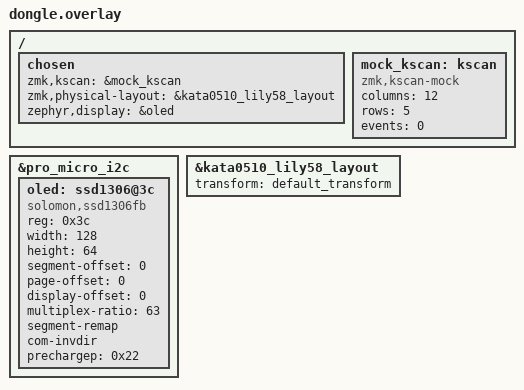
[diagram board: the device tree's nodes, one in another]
#include <dt-bindings/zmk/matrix_transform.h>
#include <layouts/kata0510/lily58.dtsi>

/ {
    chosen {
        zmk,kscan = &mock_kscan;
        zmk,physical-layout = &kata0510_lily58_layout;
        zephyr,display = &oled;
    };

    mock_kscan: kscan {
        compatible = "zmk,kscan-mock";
        columns = <12>;
        rows = <5>;
        events = <0>;
    };
};

&pro_micro_i2c {
    status = "okay";
    oled: ssd1306@3c {
        compatible = "solomon,ssd1306fb";
        reg = <0x3c>;
        width = <128>;
        height = <64>;
        segment-offset = <0>;
        page-offset = <0>;
        display-offset = <0>;
        multiplex-ratio = <63>;
        segment-remap;
        com-invdir;
        prechargep = <0x22>;
    };
};

&kata0510_lily58_layout {
    transform = <&default_transform>;
};
